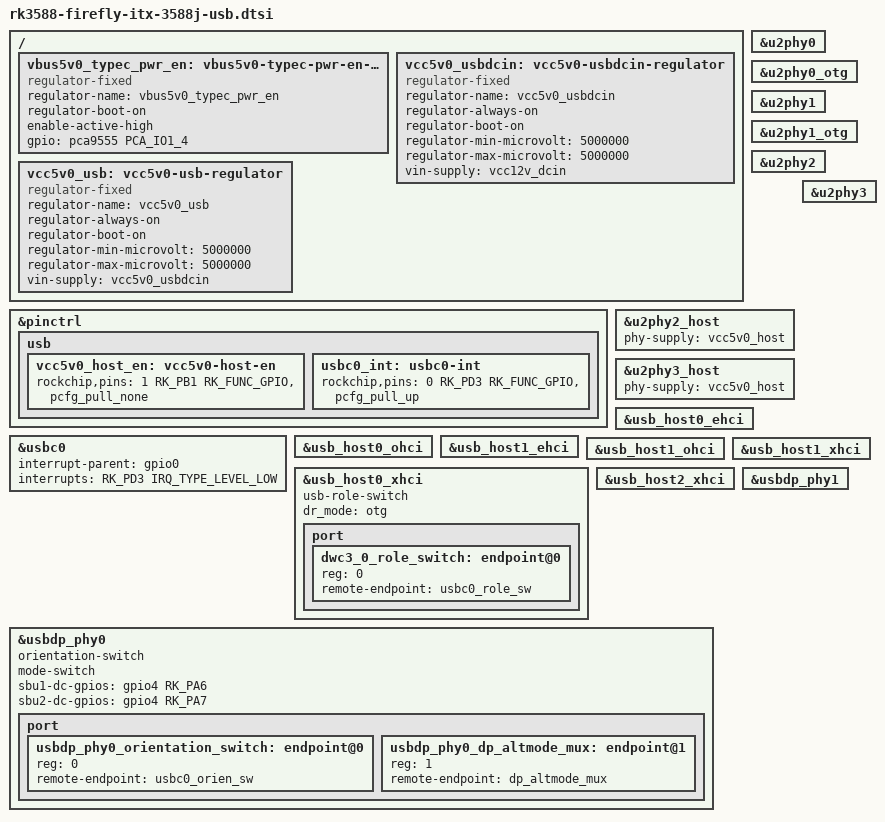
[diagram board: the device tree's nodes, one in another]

&pinctrl {

	usb {
		vcc5v0_host_en: vcc5v0-host-en {
			rockchip,pins = <1 RK_PB1 RK_FUNC_GPIO &pcfg_pull_none>;
		};

		usbc0_int: usbc0-int {
			rockchip,pins = <0 RK_PD3 RK_FUNC_GPIO &pcfg_pull_up>;
		};
	};
};

/ {
	vbus5v0_typec_pwr_en: vbus5v0-typec-pwr-en-regulator {
		compatible = "regulator-fixed";
		regulator-name = "vbus5v0_typec_pwr_en";
		regulator-boot-on;
		enable-active-high;
		status = "okay";
		gpio = <&pca9555 PCA_IO1_4 GPIO_ACTIVE_HIGH>;  //PCA_IO 14
	};

	vcc5v0_usbdcin: vcc5v0-usbdcin-regulator {
		compatible = "regulator-fixed";
		regulator-name = "vcc5v0_usbdcin";
		regulator-always-on;
		regulator-boot-on;
		regulator-min-microvolt = <5000000>;
		regulator-max-microvolt = <5000000>;
		vin-supply = <&vcc12v_dcin>;
	};

	vcc5v0_usb: vcc5v0-usb-regulator {
		compatible = "regulator-fixed";
		regulator-name = "vcc5v0_usb";
		regulator-always-on;
		regulator-boot-on;
		regulator-min-microvolt = <5000000>;
		regulator-max-microvolt = <5000000>;
		vin-supply = <&vcc5v0_usbdcin>;
	};

};

&u2phy0 {
	status = "okay";
};

&u2phy0_otg {
	// Attribute is not in the schema - obsolete?
	// rockchip,typec-vbus-det;
	status = "okay";
};

&u2phy1 {
	status = "okay";
};

&u2phy1_otg {
	status = "okay";
};

&u2phy2 {
	status = "okay";
};

&u2phy2_host {
	phy-supply = <&vcc5v0_host>;
	status = "okay";
};

&u2phy3 {
	status = "okay";
};

&u2phy3_host {
	phy-supply = <&vcc5v0_host>;
	status = "okay";
};

&usbc0 {
	status = "okay";
	interrupt-parent = <&gpio0>;
	interrupts = <RK_PD3 IRQ_TYPE_LEVEL_LOW>;
};

&usb_host0_ehci {
	status = "okay";
};

&usb_host0_ohci {
	status = "okay";
};

&usb_host1_ehci {
	status = "okay";
};

&usb_host1_ohci {
	status = "okay";
};

&usb_host0_xhci {
	usb-role-switch;
	dr_mode = "otg";
	status = "okay";

	port {
		#address-cells = <1>;
		#size-cells = <0>;

		dwc3_0_role_switch: endpoint@0 {
			reg = <0>;
			remote-endpoint = <&usbc0_role_sw>;
		};
	};
};

&usb_host1_xhci {
	status = "okay";
};

&usb_host2_xhci {
	status = "okay";
};

&usbdp_phy0 {
	orientation-switch;
	mode-switch;
	sbu1-dc-gpios = <&gpio4 RK_PA6 GPIO_ACTIVE_HIGH>;
	sbu2-dc-gpios = <&gpio4 RK_PA7 GPIO_ACTIVE_HIGH>;
	status = "okay";

	port {
		#address-cells = <1>;
		#size-cells = <0>;

		usbdp_phy0_orientation_switch: endpoint@0 {
			reg = <0>;
			remote-endpoint = <&usbc0_orien_sw>;
		};

		usbdp_phy0_dp_altmode_mux: endpoint@1 {
			reg = <1>;
			remote-endpoint = <&dp_altmode_mux>;
		};
	};
};

&usbdp_phy0 {
	status = "okay";
};

&usbdp_phy1 {
	status = "okay";
};
